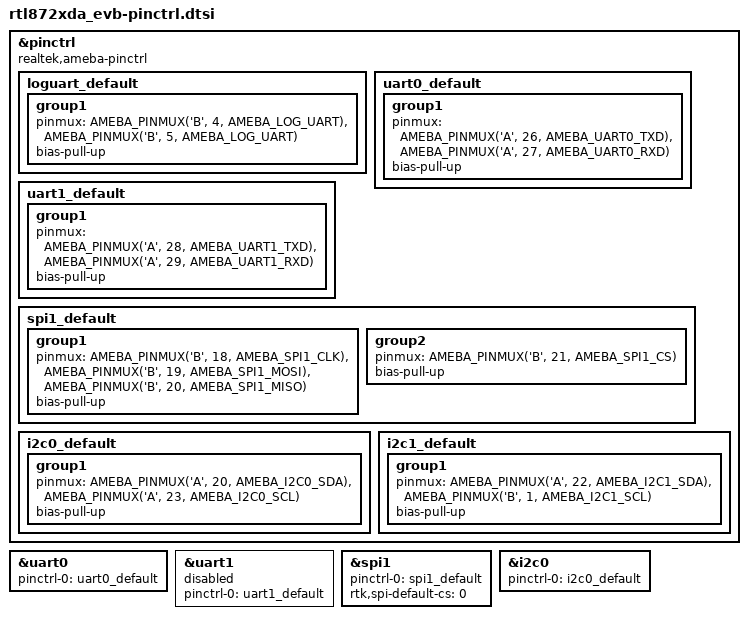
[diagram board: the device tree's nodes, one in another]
/*
 * Copyright (c) 2024 Realtek Semiconductor Corp.
 *
 * SPDX-License-Identifier: Apache-2.0
 */

#include <dt-bindings/pinctrl/realtek-amebadplus-pinctrl.h>

&pinctrl {
	compatible = "realtek,ameba-pinctrl";

	/*PA30 is SWD_CLK, PA31 is SWD_DAT(both pull-up internally)*/
	loguart_default: loguart_default {
		group1 {
			pinmux = <AMEBA_PINMUX('B', 4, AMEBA_LOG_UART)>,        /* RXD */
					 <AMEBA_PINMUX('B', 5, AMEBA_LOG_UART)>;        /* TXD */
			bias-pull-up;
		};
	};

	uart0_default: uart0_default {
		group1 {
			pinmux = <AMEBA_PINMUX('A', 26, AMEBA_UART0_TXD)>,
					 <AMEBA_PINMUX('A', 27, AMEBA_UART0_RXD)>;
			bias-pull-up;
		};
	};

	uart1_default: uart1_default {
		group1 {
			pinmux = <AMEBA_PINMUX('A', 28, AMEBA_UART1_TXD)>,
					 <AMEBA_PINMUX('A', 29, AMEBA_UART1_RXD)>;
			bias-pull-up;
		};
	};

	spi1_default: spi1_default {
		group1 {
			pinmux = <AMEBA_PINMUX('B', 18, AMEBA_SPI1_CLK)>,
					 <AMEBA_PINMUX('B', 19, AMEBA_SPI1_MOSI)>,
					 <AMEBA_PINMUX('B', 20, AMEBA_SPI1_MISO)>;
			bias-pull-up;
		};
		group2 {
			pinmux = <AMEBA_PINMUX('B', 21, AMEBA_SPI1_CS)>;
			bias-pull-up;
		};
	};

	i2c0_default: i2c0_default {
		group1 {
			pinmux = <AMEBA_PINMUX('A', 20, AMEBA_I2C0_SDA)>,
					 <AMEBA_PINMUX('A', 23, AMEBA_I2C0_SCL)>;
			bias-pull-up;
		};
	};

	i2c1_default: i2c1_default {
		group1 {
			pinmux = <AMEBA_PINMUX('A', 22, AMEBA_I2C1_SDA)>,
					 <AMEBA_PINMUX('B',  1, AMEBA_I2C1_SCL)>;
			bias-pull-up;
		};
	};
};

&uart0 {
	pinctrl-0 = <&uart0_default>;
	pinctrl-names = "default";
	status = "okay";
};

&uart1 {
	pinctrl-0 = <&uart1_default>;
	pinctrl-names = "default";
	status = "disabled";
};

&spi1 {
	pinctrl-0 = <&spi1_default>;
	pinctrl-names = "default";
	rtk,spi-default-cs = <0>;
	status = "okay";
};

&i2c0 {
	pinctrl-0 = <&i2c0_default>;
	pinctrl-names = "default";
	status = "okay";
};
